# CW32L031 register map
Vendor: Wuhan Xinyuan Semiconductor Co.,Ltd; Series: CW32L03xx; File version: 1.2
CPU: CM0+ r0p1, little endian, no MPU, no FPU, 3 interrupt priority bits
Registers are 32-bit, read-write, no defined reset value unless marked. A register's access mark holds for its fields unless they carry their own. Offsets are from the block's base; [hi:lo] are bit positions; {n}, {i} and the like mark numbered series; 'fields as' and 'values as' point back to an identical list.

## SPI1
Base 0x40013000
Same registers: SPI2 0x40003800
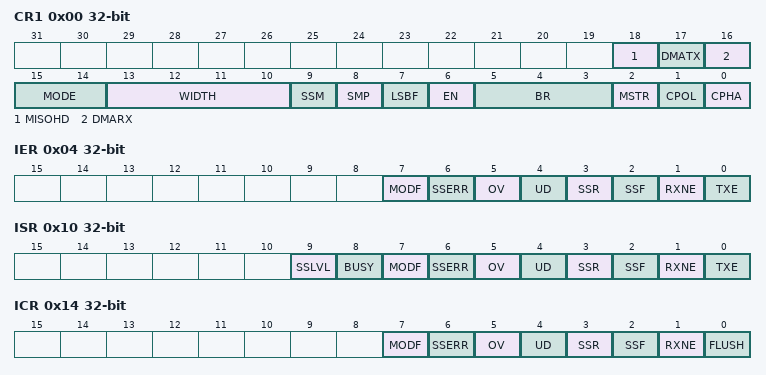
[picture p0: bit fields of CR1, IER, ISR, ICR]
0x00 CR1 — Control register1
  [18] MISOHD, [17] DMATX, [16] DMARX, [15:14] MODE, [13:10] WIDTH, [9] SSM, [8] SMP, [7] LSBF, [6] EN, [5:3] BR, [2] MSTR, [1] CPOL, [0] CPHA
0x04 IER — Interrupt enable register
  [7] MODF, [6] SSERR, [5] OV, [4] UD, [3] SSR, [2] SSF, [1] RXNE, [0] TXE
0x08 CR2 — Control register2
  [0] HDOE
0x0C SSI — Slave slect register
  [0] SSI
0x10 ISR ro — Interrupt status register
  [9] SSLVL, [8] BUSY, [7] MODF, [6] SSERR, [5] OV, [4] UD, [3] SSR, [2] SSF, [1] RXNE, [0] TXE
0x14 ICR — Interrupt flag clear register
  [7] MODF, [6] SSERR, [5] OV, [4] UD, [3] SSR, [2] SSF, [1] RXNE, [0] FLUSH
0x18 DR — Data register
  [15:0] DR

## SYSCTRL — System Ctrl
Base 0x40010000
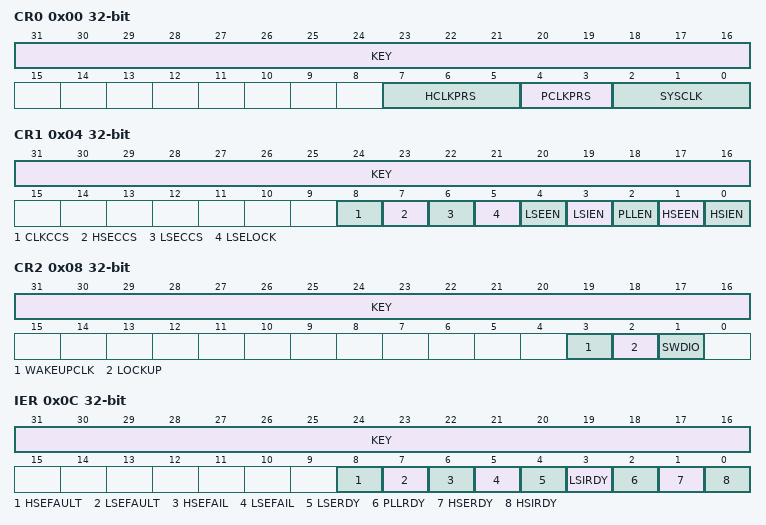
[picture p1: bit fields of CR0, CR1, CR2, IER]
0x00 CR0 — Control Reg0
  [31:16] KEY wo, [7:5] HCLKPRS, [4:3] PCLKPRS, [2:0] SYSCLK
0x04 CR1 — Control Reg1
  [31:16] KEY wo, [8] CLKCCS, [7] HSECCS, [6] LSECCS, [5] LSELOCK, [4] LSEEN, [3] LSIEN, [2] PLLEN, [1] HSEEN, [0] HSIEN
0x08 CR2 — Control Reg2
  [31:16] KEY wo, [3] WAKEUPCLK, [2] LOCKUP, [1] SWDIO
0x0C IER — Interupt Enable Reg
  [31:16] KEY wo, [8] HSEFAULT, [7] LSEFAULT, [6] HSEFAIL, [5] LSEFAIL, [4] LSERDY, [3] LSIRDY, [2] PLLRDY, [1] HSERDY, [0] HSIRDY
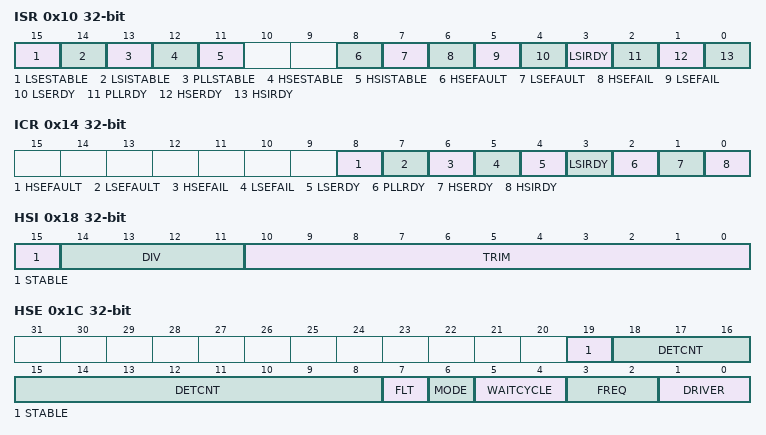
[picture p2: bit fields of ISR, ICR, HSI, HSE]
0x10 ISR ro — Interupt Status Reg
  [15] LSESTABLE, [14] LSISTABLE, [13] PLLSTABLE, [12] HSESTABLE, [11] HSISTABLE, [8] HSEFAULT, [7] LSEFAULT, [6] HSEFAIL, [5] LSEFAIL, [4] LSERDY, [3] LSIRDY, [2] PLLRDY, [1] HSERDY, [0] HSIRDY
0x14 ICR — Interupt Clear Reg
  [8] HSEFAULT, [7] LSEFAULT, [6] HSEFAIL, [5] LSEFAIL, [4] LSERDY, [3] LSIRDY, [2] PLLRDY, [1] HSERDY, [0] HSIRDY
0x18 HSI — HSI Control Reg
  [15] STABLE ro, [14:11] DIV, [10:0] TRIM
0x1C HSE — HSE Control Reg
  [19] STABLE ro, [18:8] DETCNT, [7] FLT, [6] MODE, [5:4] WAITCYCLE, [3:2] FREQ, [1:0] DRIVER
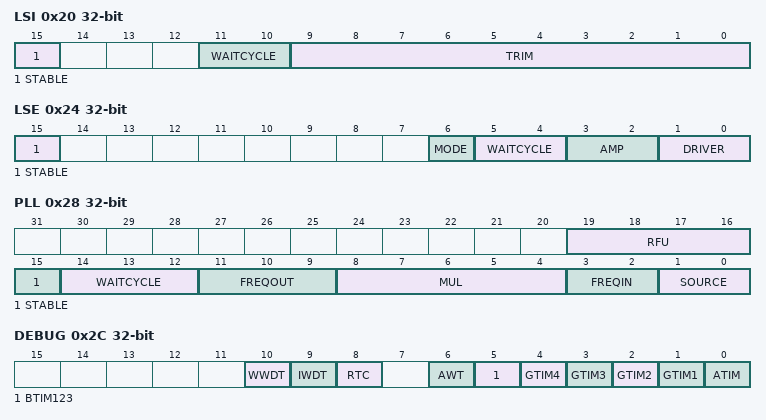
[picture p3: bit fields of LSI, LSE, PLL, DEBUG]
0x20 LSI — LSI Control Reg
  [15] STABLE ro, [11:10] WAITCYCLE, [9:0] TRIM
0x24 LSE — LSE Control Reg
  [15] STABLE ro, [6] MODE, [5:4] WAITCYCLE, [3:2] AMP, [1:0] DRIVER
0x28 PLL — PLL Control Reg
  [19:16] RFU, [15] STABLE ro, [14:12] WAITCYCLE, [11:9] FREQOUT, [8:4] MUL, [3:2] FREQIN, [1:0] SOURCE
0x2C DEBUG — Debug Control Reg
  [10] WWDT, [9] IWDT, [8] RTC, [6] AWT, [5] BTIM123, [n] GTIM{n} (n=1..4), [0] ATIM
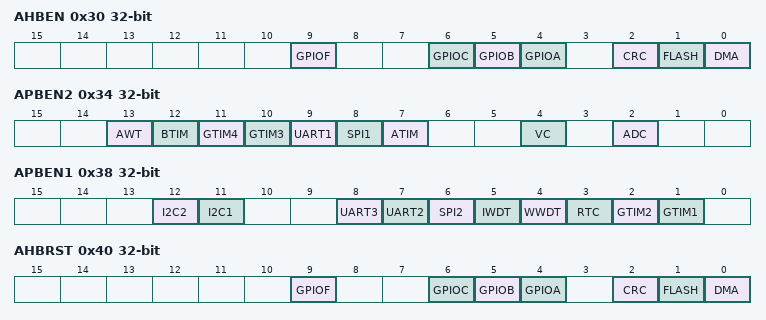
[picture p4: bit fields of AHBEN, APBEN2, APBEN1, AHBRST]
0x30 AHBEN — AHB Clock Control Reg
  [9] GPIOF, [6] GPIOC, [5] GPIOB, [4] GPIOA, [2] CRC, [1] FLASH, [0] DMA
0x34 APBEN2 — APB Clock Control Reg2
  [13] AWT, [12] BTIM, [11] GTIM4, [10] GTIM3, [9] UART1, [8] SPI1, [7] ATIM, [4] VC, [2] ADC
0x38 APBEN1 — APB Clock Control Reg1
  [12] I2C2, [11] I2C1, [8] UART3, [7] UART2, [6] SPI2, [5] IWDT, [4] WWDT, [3] RTC, [2] GTIM2, [1] GTIM1
0x40 AHBRST — AHB Reset Control Reg
  fields as AHBEN
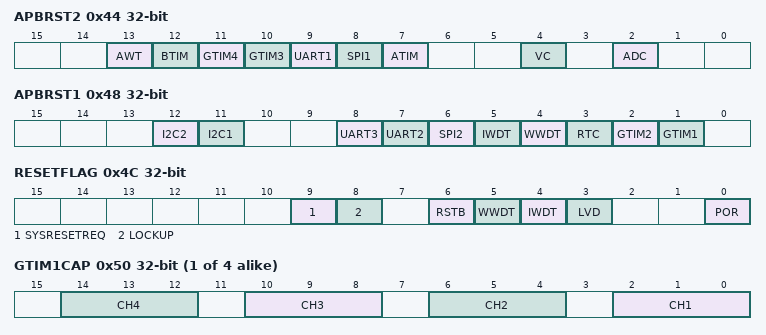
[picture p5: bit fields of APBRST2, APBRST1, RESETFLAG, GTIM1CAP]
0x44 APBRST2 — APB Reset Control Reg2
  fields as APBEN2
0x48 APBRST1 — APB Reset Control Reg1
  fields as APBEN1
0x4C RESETFLAG — Reset Status Reg
  [9] SYSRESETREQ, [8] LOCKUP, [6] RSTB, [5] WWDT, [4] IWDT, [3] LVD, [0] POR
{0x4C+4i} GTIM{i}CAP (i=1..4) — GTIM{i} CAP Control Reg
  [4n-2:4n-4] CH{n} (n=1..4)
0x60 ATIMETR — ATIM ETR Control Reg
  [2:0] ATIMETR
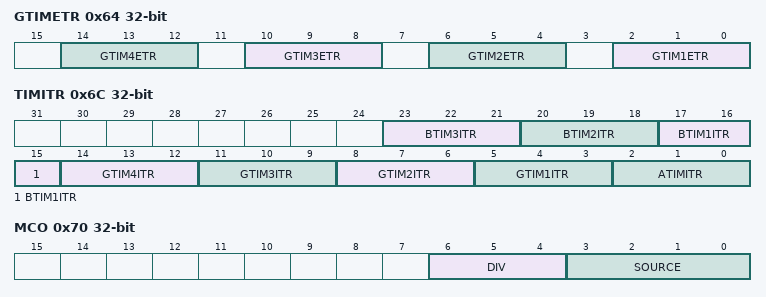
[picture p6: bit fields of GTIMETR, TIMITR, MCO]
0x64 GTIMETR — GTIM1-4 ETR Control Reg
  [4n-2:4n-4] GTIM{n}ETR (n=1..4)
0x6C TIMITR — BTIMx GTIMx ATIM ITR Control Reg
  [23:21] BTIM3ITR, [20:18] BTIM2ITR, [17:15] BTIM1ITR, [3n+2:3n] GTIM{n}ITR (n=1..4), [2:0] ATIMITR
0x70 MCO — Master Clock Output Control Reg
  [6:4] DIV, [3:0] SOURCE
0x74 IRMOD — IR MOD Control Reg
  [3:0] MOD

## UART1
Base 0x40013800
Same registers: UART2 0x40004400, UART3 0x40004800
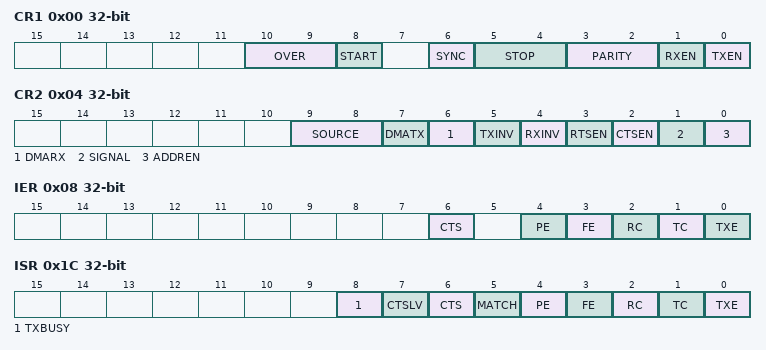
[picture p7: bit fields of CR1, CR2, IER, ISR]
0x00 CR1 — Control register1
  [10:9] OVER, [8] START, [6] SYNC, [5:4] STOP, [3:2] PARITY, [1] RXEN, [0] TXEN
0x04 CR2 — Control register2
  [9:8] SOURCE, [7] DMATX, [6] DMARX, [5] TXINV, [4] RXINV, [3] RTSEN, [2] CTSEN, [1] SIGNAL, [0] ADDREN
0x08 IER — Interrupt enable register
  [6] CTS — CTS change
  [4] PE — Parity error
  [3] FE — Frame error
  [2] RC — Receive complete
  [1] TC — Transmit complete
  [0] TXE — TxBuf empty
0x0C BRRI
  [15:0] BRRI
0x10 BRRF
  [3:0] BRRF
0x1C ISR ro — Interrupt status register
  [8] TXBUSY
  [7] CTSLV — CTS PIN level
  [6] CTS — CTS change
  [5] MATCH — Slave addr match
  [4] PE — Parity error
  [3] FE — Frame error
  [2] RC — Receive complete
  [1] TC — Transmit complete
  [0] TXE — TxBuf empty
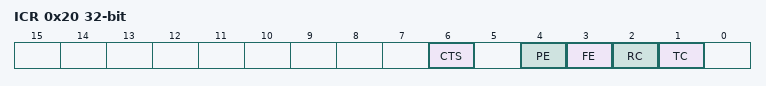
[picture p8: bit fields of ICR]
0x20 ICR — Interrupt flag clear register
  [6] CTS — CTS change
  [4] PE — Parity error
  [3] FE — Frame error
  [2] RC — Receive complete
  [1] TC — Transmit complete
0x24 RDR ro — Data reg for read
  [8:0] RDR
0x28 TDR wo — Data reg for write
  [8:0] TDR
0x30 ADDR — Slave addr
  [7:0] ADDR
0x34 MASK — Slave addr mask
  [7:0] MASK

## VC1
Base 0x40012A00
Same registers: VC2 0x40012A10
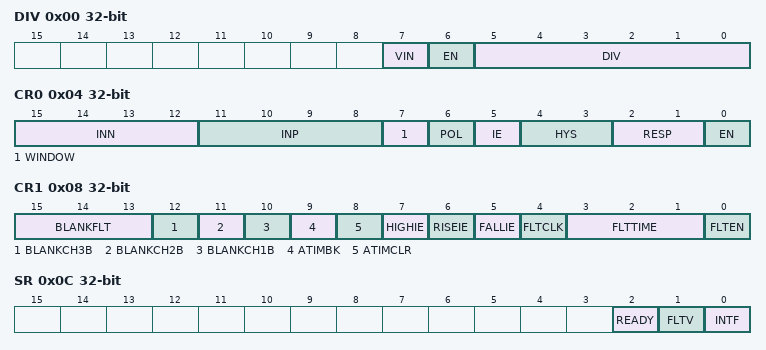
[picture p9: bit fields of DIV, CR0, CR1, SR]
0x00 DIV
  [7] VIN, [6] EN, [5:0] DIV
0x04 CR0 — Control register0
  [15:12] INN, [11:8] INP, [7] WINDOW, [6] POL, [5] IE, [4:3] HYS, [2:1] RESP, [0] EN
0x08 CR1 — Control register1
  [15:13] BLANKFLT, [12] BLANKCH3B, [11] BLANKCH2B, [10] BLANKCH1B, [9] ATIMBK, [8] ATIMCLR, [7] HIGHIE, [6] RISEIE, [5] FALLIE, [4] FLTCLK, [3:1] FLTTIME, [0] FLTEN
0x0C SR — Status register
  [2] READY ro, [1] FLTV ro, [0] INTF

## WWDT
Base 0x40002C00
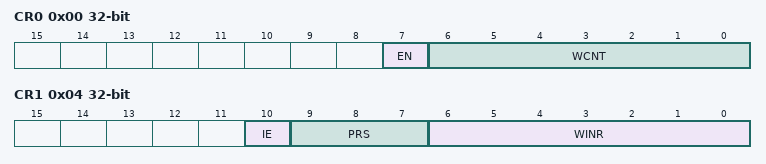
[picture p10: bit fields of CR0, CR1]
0x00 CR0 — Control register1
  [7] EN, [6:0] WCNT
0x04 CR1 — Control register2
  [10] IE, [9:7] PRS, [6:0] WINR
0x08 SR — Status register
  [0] POV
